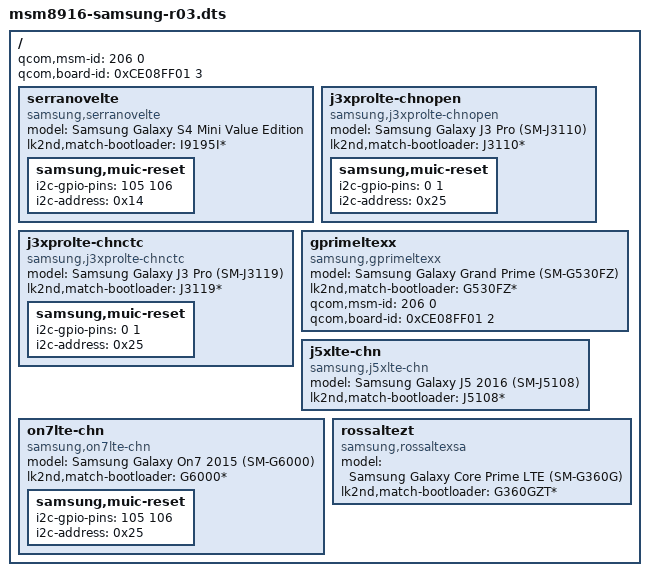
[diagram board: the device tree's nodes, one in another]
// SPDX-License-Identifier: GPL-2.0-only

/dts-v1/;

#include <skeleton.dtsi>
#include <lk2nd.h>

/ {
	// This is used by the bootloader to find the correct DTB
	qcom,msm-id = <206 0>;
	qcom,board-id = <0xCE08FF01 3>;

	serranovelte {
		model = "Samsung Galaxy S4 Mini Value Edition";
		compatible = "samsung,serranovelte", "qcom,msm8916", "lk2nd,device";
		lk2nd,match-bootloader = "I9195I*";

		samsung,muic-reset {
			i2c-gpio-pins = <105 106>;
			i2c-address = <0x14>;
		};
	};

	j3xprolte-chnopen {
		model = "Samsung Galaxy J3 Pro (SM-J3110)";
		compatible = "samsung,j3xprolte-chnopen", "qcom,msm8916", "lk2nd,device";
		lk2nd,match-bootloader = "J3110*";
		samsung,muic-reset {
			i2c-gpio-pins = <0 1>;
			i2c-address = <0x25>;
		};
	};

	j3xprolte-chnctc {
		model = "Samsung Galaxy J3 Pro (SM-J3119)";
		compatible = "samsung,j3xprolte-chnctc", "qcom,msm8916", "lk2nd,device";
		lk2nd,match-bootloader = "J3119*";

		samsung,muic-reset {
			i2c-gpio-pins = <0 1>;
			i2c-address = <0x25>;
		};
	};

	gprimeltexx {
		model = "Samsung Galaxy Grand Prime (SM-G530FZ)";
		compatible = "samsung,gprimeltexx", "qcom,msm8916", "lk2nd,device";
		lk2nd,match-bootloader = "G530FZ*";
		qcom,msm-id = <206 0>;
		qcom,board-id = <0xCE08FF01 2>;
		#include "msm8916-samsung-gprime.dtsi"
	};

	j5xlte-chn {
		model = "Samsung Galaxy J5 2016 (SM-J5108)";
		compatible = "samsung,j5xlte-chn", "qcom,msm8916", "lk2nd,device";
		lk2nd,match-bootloader = "J5108*";

		#include "msm8916-samsung-j5.dtsi"
	};

	on7lte-chn {
		model = "Samsung Galaxy On7 2015 (SM-G6000)";
		compatible = "samsung,on7lte-chn", "qcom,msm8916", "lk2nd,device";
		lk2nd,match-bootloader = "G6000*";

		samsung,muic-reset {
			i2c-gpio-pins = <105 106>;
			i2c-address = <0x25>;
		};
	};

	/*
	 * Before building for rossaltezt, please comment out all dtbs except
	 * "$(LOCAL_DIR)/msm8916-samsung-r03.dtb" at './rules.mk'.
	 * rossaltezt doesn't work with multi-dtbs; only goes into "Download mode".
	 */
	rossaltezt {
		model = "Samsung Galaxy Core Prime LTE (SM-G360G)";
		compatible = "samsung,rossaltexsa", "qcom,msm8916", "lk2nd,device";
		lk2nd,match-bootloader = "G360GZT*";
		#include "msm8916-samsung-cprime.dtsi"
	};
};
